# AT91SAM9X25 register map
Vendor: Atmel; Series: SAM9X; File version: 20130207
Atmel AT91SAM9X25 device: ARM926EJ Embedded Microprocessor Unit, 400MHz, Dual Ethernet and CAN, HS USB, LPDDR/DDR2/MLC NAND support, 217 Pins (refer to http://www.atmel.com/devices/SAM9X25.aspx for more)
Registers are 32-bit, read-write, reset 0x0 unless marked. A register's access mark holds for its fields unless they carry their own. Offsets are from the block's base; lines under a group give offsets from that group; [hi:lo] are bit positions; {n}, {i} and the like mark numbered series; 'fields as' and 'values as' point back to an identical list; <NAME> marks a mode.

## Memory map
0x00400000 SMD size 0x100000 — Software Modem Device
0xF0000000 SPI0 size 0x4000 — Serial Peripheral Interface 0
0xF0004000 SPI1 size 0x4000 — Serial Peripheral Interface 1
0xF0008000 HSMCI0 size 0x4000 — High Speed MultiMedia Card Interface 0
0xF000C000 HSMCI1 size 0x4000 — High Speed MultiMedia Card Interface 1
0xF0010000 SSC size 0x4000 — Synchronous Serial Controller
0xF8000000 CAN0 size 0x4000 — Controller Area Network 0
0xF8004000 CAN1 size 0x4000 — Controller Area Network 1
0xF8008000 TC0 size 0x4000 — Timer Counter 0
0xF800C000 TC1 size 0x4000 — Timer Counter 1
0xF8010000 TWI0 size 0x4000 — Two-wire Interface 0
0xF8014000 TWI1 size 0x4000 — Two-wire Interface 1
0xF8018000 TWI2 size 0x4000 — Two-wire Interface 2
0xF801C000 USART0 size 0x4000 — Universal Synchronous Asynchronous Receiver Transmitter 0
0xF8020000 USART1 size 0x4000 — Universal Synchronous Asynchronous Receiver Transmitter 1
0xF8024000 USART2 size 0x4000 — Universal Synchronous Asynchronous Receiver Transmitter 2
0xF8028000 USART3 size 0x4000 — Universal Synchronous Asynchronous Receiver Transmitter 3
0xF802C000 EMAC0 size 0x4000 — Ethernet MAC 10/100 0
0xF8030000 EMAC1 size 0x4000 — Ethernet MAC 10/100 1
0xF8034000 PWM size 0x4000 — Pulse Width Modulation Controller
0xF803C000 UDPHS size 0x4000 — USB High Speed Device Port
0xF8040000 UART0 size 0x4000 — Universal Asynchronous Receiver Transmitter 0
0xF8044000 UART1 size 0x4000 — Universal Asynchronous Receiver Transmitter 1
0xF804C000 ADC size 0x4000 — Analog-to-Digital Converter
0xFFFFDE00 MATRIX size 0x200 — AHB Bus Matrix
0xFFFFE000 PMECC size 0x600 — Programmable Multibit Error Corrected Code Controller
0xFFFFE600 PMERRLOC size 0x200 — Programmable Multibit ECC Error Location
0xFFFFE800 DDRSDRC size 0x200 — DDR_SDR SDRAM Controller
0xFFFFEA00 SMC size 0x200 — Static Memory Controller
0xFFFFEC00 DMAC0 size 0x200 — DMA Controller 0
0xFFFFEE00 DMAC1 size 0x200 — DMA Controller 1
0xFFFFF000 AIC size 0x200 — Advanced Interrupt Controller
0xFFFFF200 DBGU size 0x200 — Debug Unit
0xFFFFF400 PIOA size 0x200 — Parallel Input/Output Controller A
0xFFFFF600 PIOB size 0x200 — Parallel Input/Output Controller B
0xFFFFF800 PIOC size 0x200 — Parallel Input/Output Controller C
0xFFFFFA00 PIOD size 0x200 — Parallel Input/Output Controller D
0xFFFFFC00 PMC size 0x200 — Power Management Controller
0xFFFFFE00 RSTC size 0xC — Reset Controller
0xFFFFFE10 SHDWC size 0xC — Shutdown Controller
0xFFFFFE30 PIT size 0x10 — Periodic Interval Timer
0xFFFFFE40 WDT size 0xC — Watchdog Timer
0xFFFFFE50 SCKC size 0x4 — Slow Clock Controller
0xFFFFFE54 BSC size 0x4 — Boot Sequence Controller
0xFFFFFE60 GPBR size 0x10 — General Purpose Backup Register
0xFFFFFEB0 RTC size 0x30 — Real-time Clock

## Interrupts
0 FIQ (AIC)
1 DBGU
2 PIOA
3 PIOC
4 SMD
5 USART0
6 USART1
7 USART2
8 USART3
9 TWI0
10 TWI1
11 TWI2
12 HSMCI0
13 SPI0
14 SPI1
15 UART0
16 UART1
17 TC0
18 PWM
19 ADC
20 DMAC0
21 DMAC1
23 UDPHS
24 EMAC0
26 HSMCI1
27 EMAC1
28 SSC
29 CAN0
30 CAN1
31 IRQ (AIC)

## SPI0 — Serial Peripheral Interface 0
Base 0xF0000000; register names take the prefix SPI0_
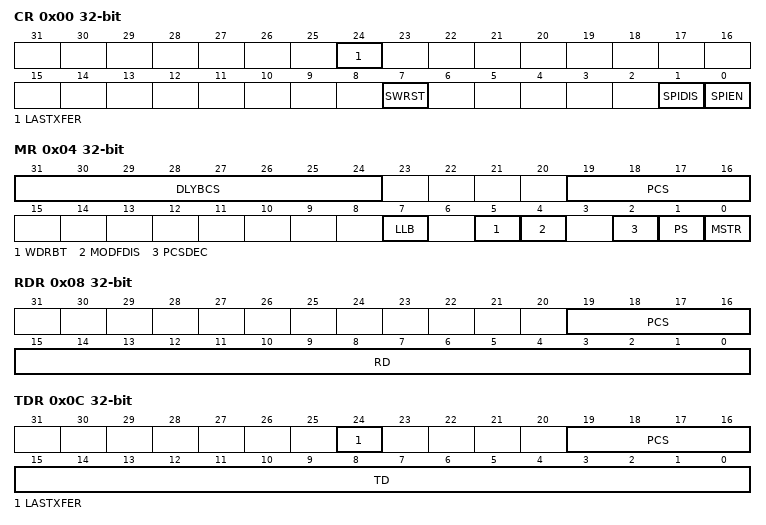
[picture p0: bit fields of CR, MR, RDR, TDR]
0x00 CR wo reset not defined — Control Register
  [24] LASTXFER — Last Transfer
  [7] SWRST — SPI Software Reset
  [1] SPIDIS — SPI Disable
  [0] SPIEN — SPI Enable
0x04 MR — Mode Register
  [31:24] DLYBCS — Delay Between Chip Selects
  [19:16] PCS — Peripheral Chip Select
  [7] LLB — Local Loopback Enable
  [5] WDRBT — Wait Data Read Before Transfer
  [4] MODFDIS — Mode Fault Detection
  [2] PCSDEC — Chip Select Decode
  [1] PS — Peripheral Select
  [0] MSTR — Master/Slave Mode
0x08 RDR ro — Receive Data Register
  [19:16] PCS — Peripheral Chip Select
  [15:0] RD — Receive Data
0x0C TDR wo reset not defined — Transmit Data Register
  [24] LASTXFER — Last Transfer
  [19:16] PCS — Peripheral Chip Select
  [15:0] TD — Transmit Data
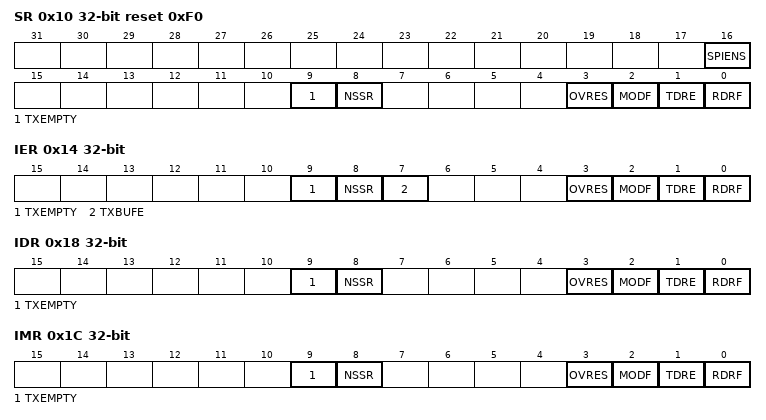
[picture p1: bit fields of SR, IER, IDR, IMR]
0x10 SR ro reset 0xF0 — Status Register
  [16] SPIENS — SPI Enable Status
  [9] TXEMPTY — Transmission Registers Empty
  [8] NSSR — NSS Rising
  [3] OVRES — Overrun Error Status
  [2] MODF — Mode Fault Error
  [1] TDRE — Transmit Data Register Empty
  [0] RDRF — Receive Data Register Full
0x14 IER wo reset not defined — Interrupt Enable Register
  [9] TXEMPTY — Transmission Registers Empty Enable
  [8] NSSR — NSS Rising Interrupt Enable
  [7] TXBUFE
  [3] OVRES — Overrun Error Interrupt Enable
  [2] MODF — Mode Fault Error Interrupt Enable
  [1] TDRE — SPI Transmit Data Register Empty Interrupt Enable
  [0] RDRF — Receive Data Register Full Interrupt Enable
0x18 IDR wo reset not defined — Interrupt Disable Register
  [9] TXEMPTY — Transmission Registers Empty Disable
  [8] NSSR — NSS Rising Interrupt Disable
  [3] OVRES — Overrun Error Interrupt Disable
  [2] MODF — Mode Fault Error Interrupt Disable
  [1] TDRE — SPI Transmit Data Register Empty Interrupt Disable
  [0] RDRF — Receive Data Register Full Interrupt Disable
0x1C IMR ro — Interrupt Mask Register
  [9] TXEMPTY — Transmission Registers Empty Mask
  [8] NSSR — NSS Rising Interrupt Mask
  [3] OVRES — Overrun Error Interrupt Mask
  [2] MODF — Mode Fault Error Interrupt Mask
  [1] TDRE — SPI Transmit Data Register Empty Interrupt Mask
  [0] RDRF — Receive Data Register Full Interrupt Mask
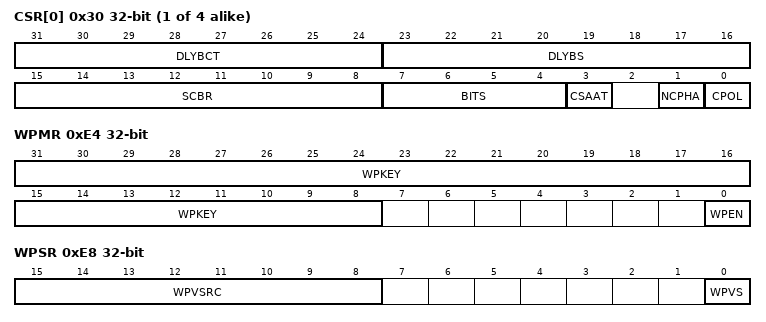
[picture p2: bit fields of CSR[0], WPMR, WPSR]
{0x30+4i} CSR[{i}] (i=0..3) reset not defined — Chip Select Register
  [31:24] DLYBCT — Delay Between Consecutive Transfers
  [23:16] DLYBS — Delay Before SPCK
  [15:8] SCBR — Serial Clock Baud Rate
  [7:4] BITS — Bits Per Transfer
    {v}={v+8}_BIT ({v+8} bits for transfer) (v=0..8)
  [3] CSAAT — Chip Select Active After Transfer
  [1] NCPHA — Clock Phase
  [0] CPOL — Clock Polarity
0xE4 WPMR — Write Protection Control Register
  [31:8] WPKEY — Write Protection Key Password
  [0] WPEN — Write Protection Enable
0xE8 WPSR ro — Write Protection Status Register
  [15:8] WPVSRC — Write Protection Violation Source
  [0] WPVS — Write Protection Violation Status

## SPI1 — Serial Peripheral Interface 1
Base 0xF0004000; register names take the prefix SPI1_
Registers as SPI0.

## Notices in the file
SAM Software Package License
Copyright (c) 2013, Atmel Corporation
All rights reserved.
Redistribution and use in source and binary forms, with or without
modification, are permitted provided that the following condition is met:
- Redistributions of source code must retain the above copyright notice,
this list of conditions and the disclaimer below.
Atmel's name may not be used to endorse or promote products derived from
this software without specific prior written permission.
DISCLAIMER:  THIS SOFTWARE IS PROVIDED BY ATMEL "AS IS" AND ANY EXPRESS OR
IMPLIED WARRANTIES, INCLUDING, BUT NOT LIMITED TO, THE IMPLIED WARRANTIES OF
MERCHANTABILITY, FITNESS FOR A PARTICULAR PURPOSE AND NON-INFRINGEMENT ARE
DISCLAIMED. IN NO EVENT SHALL ATMEL BE LIABLE FOR ANY DIRECT, INDIRECT,
INCIDENTAL, SPECIAL, EXEMPLARY, OR CONSEQUENTIAL DAMAGES (INCLUDING, BUT NOT
LIMITED TO, PROCUREMENT OF SUBSTITUTE GOODS OR SERVICES; LOSS OF USE, DATA,
OR PROFITS; OR BUSINESS INTERRUPTION) HOWEVER CAUSED AND ON ANY THEORY OF
LIABILITY, WHETHER IN CONTRACT, STRICT LIABILITY, OR TORT (INCLUDING
NEGLIGENCE OR OTHERWISE) ARISING IN ANY WAY OUT OF THE USE OF THIS SOFTWARE,
EVEN IF ADVISED OF THE POSSIBILITY OF SUCH DAMAGE.
